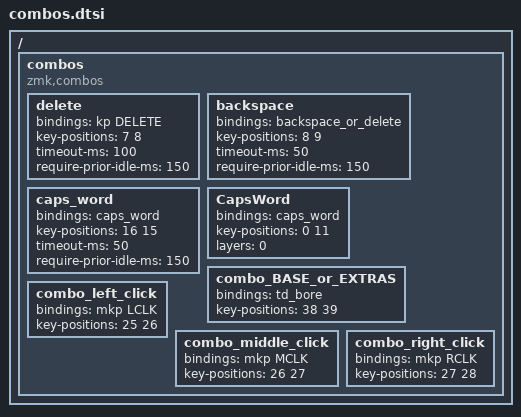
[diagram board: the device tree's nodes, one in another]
/ {
    combos {
        compatible = "zmk,combos";

/*                                      42 KEY MATRIX / LAYOUT MAPPING

  ╭────────────────────────┬────────────────────────╮ ╭─────────────────────────┬─────────────────────────╮
  │  0   1   2   3   4   5 │  6   7   8   9  10  11 │ │ LT5 LT4 LT3 LT2 LT1 LT0 │ RT0 RT1 RT2 RT3 RT4 RT5 │
  │ 12  13  14  15  16  17 │ 18  19  20  21  22  23 │ │ LM5 LM4 LM3 LM2 LM1 LM0 │ RM0 RM1 RM2 RM3 RM4 RM5 │
  │ 24  25  26  27  28  29 │ 30  31  32  33  34  35 │ │ LB5 LB4 LB3 LB2 LB1 LB0 │ RB0 RB1 RB2 RB3 RB4 RB5 │
  ╰───────────╮ 36  37  38 │ 39  40  41 ╭───────────╯ ╰───────────╮ LH2 LH1 LH0 │ RH0 RH1 RH2 ╭───────────╯
              ╰────────────┴────────────╯                         ╰─────────────┴─────────────╯             */
        delete {
            bindings = <&kp DELETE>;
            key-positions = <7 8>;
            timeout-ms = <100>;
            require-prior-idle-ms = <150>;
        };

        backspace {
            bindings = <&backspace_or_delete>;
            key-positions = <8 9>;
            timeout-ms = <50>;
            require-prior-idle-ms = <150>;
        };

        caps_word {
            bindings = <&caps_word>;
            key-positions = <16 15>;
            timeout-ms = <50>;
            require-prior-idle-ms = <150>;
        };

        CapsWord {
            bindings = <&caps_word>;
            key-positions = <0 11>;
            layers = <0>;
        };

        combo_BASE_or_EXTRAS {
            bindings = <&td_bore>;
            key-positions = <38 39>;
        };
        
        combo_left_click {
            bindings = <&mkp LCLK>;
            key-positions = <25 26>;
        };
        
        combo_middle_click {
            bindings = <&mkp MCLK>;
            key-positions = <26 27>;
        };

        combo_right_click {
            bindings = <&mkp RCLK>;
            key-positions = <27 28>;
        };
    };
};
